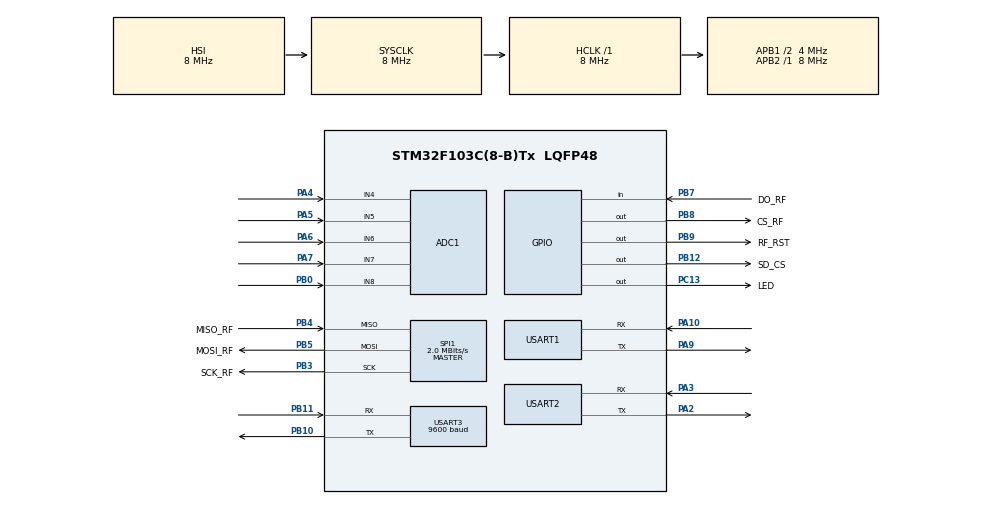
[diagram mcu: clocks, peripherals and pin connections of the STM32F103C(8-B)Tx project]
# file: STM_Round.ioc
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ADC1.Channel-0\#ChannelRegularConversion=ADC_CHANNEL_4
ADC1.Channel-1\#ChannelRegularConversion=ADC_CHANNEL_5
ADC1.Channel-2\#ChannelRegularConversion=ADC_CHANNEL_6
ADC1.Channel-3\#ChannelRegularConversion=ADC_CHANNEL_7
ADC1.Channel-4\#ChannelRegularConversion=ADC_CHANNEL_8
ADC1.ContinuousConvMode=ENABLE
ADC1.NbrOfConversion=5
ADC1.NbrOfConversionFlag=1
ADC1.Rank-0\#ChannelRegularConversion=1
ADC1.Rank-1\#ChannelRegularConversion=2
ADC1.Rank-2\#ChannelRegularConversion=3
ADC1.Rank-3\#ChannelRegularConversion=4
ADC1.Rank-4\#ChannelRegularConversion=5
ADC1.SamplingTime-0\#ChannelRegularConversion=ADC_SAMPLETIME_239CYCLES_5
ADC1.SamplingTime-1\#ChannelRegularConversion=ADC_SAMPLETIME_239CYCLES_5
ADC1.SamplingTime-2\#ChannelRegularConversion=ADC_SAMPLETIME_239CYCLES_5
ADC1.SamplingTime-3\#ChannelRegularConversion=ADC_SAMPLETIME_239CYCLES_5
ADC1.SamplingTime-4\#ChannelRegularConversion=ADC_SAMPLETIME_239CYCLES_5
ADC1.master=1
Dma.ADC1.1.Direction=DMA_PERIPH_TO_MEMORY
Dma.ADC1.1.Instance=DMA1_Channel1
Dma.ADC1.1.MemDataAlignment=DMA_MDATAALIGN_HALFWORD
Dma.ADC1.1.MemInc=DMA_MINC_ENABLE
Dma.ADC1.1.Mode=DMA_CIRCULAR
Dma.ADC1.1.PeriphDataAlignment=DMA_PDATAALIGN_HALFWORD
Dma.ADC1.1.PeriphInc=DMA_PINC_DISABLE
Dma.ADC1.1.Priority=DMA_PRIORITY_LOW
Dma.Request0=USART2_RX
Dma.Request1=ADC1
Dma.Request2=USART1_RX
Dma.USART1_RX.2.Direction=DMA_PERIPH_TO_MEMORY
Dma.USART1_RX.2.Instance=DMA1_Channel5
Dma.USART1_RX.2.MemDataAlignment=DMA_MDATAALIGN_BYTE
Dma.USART1_RX.2.MemInc=DMA_MINC_ENABLE
Dma.USART1_RX.2.Mode=DMA_NORMAL
Dma.USART1_RX.2.PeriphDataAlignment=DMA_PDATAALIGN_BYTE
Dma.USART1_RX.2.PeriphInc=DMA_PINC_DISABLE
Dma.USART1_RX.2.Priority=DMA_PRIORITY_LOW
Dma.USART2_RX.0.Direction=DMA_PERIPH_TO_MEMORY
Dma.USART2_RX.0.Instance=DMA1_Channel6
Dma.USART2_RX.0.MemDataAlignment=DMA_MDATAALIGN_BYTE
Dma.USART2_RX.0.MemInc=DMA_MINC_ENABLE
Dma.USART2_RX.0.Mode=DMA_NORMAL
Dma.USART2_RX.0.PeriphDataAlignment=DMA_PDATAALIGN_BYTE
Dma.USART2_RX.0.PeriphInc=DMA_PINC_DISABLE
Dma.USART2_RX.0.Priority=DMA_PRIORITY_LOW
Mcu.Family=STM32F1
Mcu.Name=STM32F103C(8-B)Tx
Mcu.Package=LQFP48
NVIC.DMA1_Channel1_IRQn=true\:0\:0\:false\:false\:true\:false\:true
NVIC.DMA1_Channel5_IRQn=true\:0\:0\:false\:false\:true\:false\:true
NVIC.DMA1_Channel6_IRQn=true\:1\:0\:true\:true\:true\:2\:false\:true
NVIC.PriorityGroup=NVIC_PRIORITYGROUP_4
NVIC.USART1_IRQn=true\:1\:0\:true\:true\:true\:3\:true\:true
NVIC.USART2_IRQn=true\:1\:0\:true\:true\:true\:4\:true\:true
NVIC.USART3_IRQn=true\:1\:0\:true\:true\:true\:5\:true\:true
PA10.Mode=Asynchronous
PA10.Signal=USART1_RX
PA13.Mode=Serial_Wire
PA13.Signal=SYS_JTMS-SWDIO
PA14.Mode=Serial_Wire
PA14.Signal=SYS_JTCK-SWCLK
PA2.Mode=Asynchronous
PA2.Signal=USART2_TX
PA3.Mode=Asynchronous
PA3.Signal=USART2_RX
PA4.Signal=ADCx_IN4
PA5.Signal=ADCx_IN5
PA6.Signal=ADCx_IN6
PA7.Signal=ADCx_IN7
PA9.Mode=Asynchronous
PA9.Signal=USART1_TX
PB0.Signal=ADCx_IN8
PB10.Mode=Asynchronous
PB10.Signal=USART3_TX
PB11.Mode=Asynchronous
PB11.Signal=USART3_RX
PB12.GPIO_Label=SD_CS
PB12.GPIO_Speed=GPIO_SPEED_FREQ_MEDIUM
PB12.Signal=GPIO_Output
PB3.GPIO_Label=SCK_RF
PB3.Mode=Full_Duplex_Master
PB3.Signal=SPI1_SCK
PB4.GPIO_Label=MISO_RF
PB4.Mode=Full_Duplex_Master
PB4.Signal=SPI1_MISO
PB5.GPIO_Label=MOSI_RF
PB5.Mode=Full_Duplex_Master
PB5.Signal=SPI1_MOSI
PB7.GPIO_Label=DO_RF
PB7.Signal=GPIO_Input
PB8.GPIO_Label=CS_RF
PB8.GPIO_Speed=GPIO_SPEED_FREQ_MEDIUM
PB8.PinState=GPIO_PIN_SET
PB8.Signal=GPIO_Output
PB9.GPIO_Label=RF_RST
PB9.PinState=GPIO_PIN_SET
PB9.Signal=GPIO_Output
PC13-TAMPER-RTC.GPIO_Label=LED
PC13-TAMPER-RTC.Signal=GPIO_Output
ProjectManager.HeapSize=0x200
ProjectManager.StackSize=0x400
ProjectManager.TargetToolchain=STM32CubeIDE
RCC.ADCPresc=RCC_ADCPCLK2_DIV6
RCC.AHBFreq_Value=8000000
RCC.APB1CLKDivider=RCC_HCLK_DIV2
RCC.APB1Freq_Value=4000000
RCC.APB1TimFreq_Value=8000000
RCC.APB2Freq_Value=8000000
RCC.APB2TimFreq_Value=8000000
RCC.HCLKFreq_Value=8000000
RCC.PLLMUL=RCC_PLL_MUL9
RCC.SYSCLKFreq_VALUE=8000000
RCC.USBFreq_Value=36000000
SH.ADCx_IN4.0=ADC1_IN4,IN4
SH.ADCx_IN5.0=ADC1_IN5,IN5
SH.ADCx_IN6.0=ADC1_IN6,IN6
SH.ADCx_IN7.0=ADC1_IN7,IN7
SH.ADCx_IN8.0=ADC1_IN8,IN8
SPI1.BaudRatePrescaler=SPI_BAUDRATEPRESCALER_4
SPI1.CalculateBaudRate=2.0 MBits/s
SPI1.Direction=SPI_DIRECTION_2LINES
SPI1.Mode=SPI_MODE_MASTER
SPI1.VirtualType=VM_MASTER
USART1.VirtualMode=VM_ASYNC
USART1.WordLength=WORDLENGTH_8B
USART2.VirtualMode=VM_ASYNC
USART3.BaudRate=9600
USART3.VirtualMode=VM_ASYNC
board=custom

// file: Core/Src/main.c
/* USER CODE BEGIN Header */
/**
 ******************************************************************************
 * @file           : main.c
 * @brief          : Main program body
 ******************************************************************************
 * @attention
 *
 * <h2><center>&copy; Copyright (c) 2021 STMicroelectronics.
 * All rights reserved.</center></h2>
 *
 * This software component is licensed by ST under BSD 3-Clause license,
 * the "License"; You may not use this file except in compliance with the
 * License. You may obtain a copy of the License at:
 *                        opensource.org/licenses/BSD-3-Clause
 *
 ******************************************************************************
 */
/* USER CODE END Header */
#include "main.h"
#include "adc.h"
#include "dma.h"
#include "spi.h"
#include "usart.h"
#include "gpio.h"

/* USER CODE BEGIN Includes */

#include "Funkcje.h"
#include <stdio.h>

/* USER CODE END Includes */

/* USER CODE BEGIN PV */

char odp[100] = "TNWN;DSTA";

/* USER CODE END PV */

void SystemClock_Config(void);
static void MX_NVIC_Init(void);

int main(void)
{

  /* MCU Configuration--------------------------------------------------------*/

  /* Reset of all peripherals, Initializes the Flash interface and the Systick. */
  HAL_Init();

  /* Configure the system clock */
  SystemClock_Config();

  /* Initialize all configured peripherals */
  MX_GPIO_Init();
  MX_DMA_Init();
  MX_SPI1_Init();
  MX_USART1_UART_Init();
  MX_USART2_UART_Init();
  MX_USART3_UART_Init();
  MX_ADC1_Init();

  /* Initialize interrupts */
  MX_NVIC_Init();
  /* USER CODE BEGIN 2 */

	HAL_Delay(1000);
	initAll();

  /* USER CODE END 2 */

  /* Infinite loop */
  /* USER CODE BEGIN WHILE */
	while (1) {

		// Sprawdzanie, czy przyszły dane z LoRy:
		loraLoop();
		if (loraBuffer[0] != 0)	loraReaction();

		GPS_Process();

		// Zapisywanie każdej ramki we flashu ESP:
		if (uwTick - tfsStruct.saveTimer > SAVE_PERIOD) {

			tfsStruct.saveTimer = uwTick;
			updateFrame();
		}

		// Wysyłanie jednej ramki co jakiś czas:
		if (uwTick - tfsStruct.frameTimer > FRAME_PERIOD) {

			tfsStruct.frameTimer = uwTick;
			generateAndSendFrame();
		}

    /* USER CODE END WHILE */

	}
}

void SystemClock_Config(void)
{
  RCC_OscInitTypeDef RCC_OscInitStruct = {0};
  RCC_ClkInitTypeDef RCC_ClkInitStruct = {0};
  RCC_PeriphCLKInitTypeDef PeriphClkInit = {0};

  /** Initializes the RCC Oscillators according to the specified parameters
  * in the RCC_OscInitTypeDef structure.
  */
  RCC_OscInitStruct.OscillatorType = RCC_OSCILLATORTYPE_HSI;
  RCC_OscInitStruct.HSIState = RCC_HSI_ON;
  RCC_OscInitStruct.HSICalibrationValue = RCC_HSICALIBRATION_DEFAULT;
  RCC_OscInitStruct.PLL.PLLState = RCC_PLL_NONE;
  if (HAL_RCC_OscConfig(&RCC_OscInitStruct) != HAL_OK)
  {
    Error_Handler();
  }
  /** Initializes the CPU, AHB and APB buses clocks
  */
  RCC_ClkInitStruct.ClockType = RCC_CLOCKTYPE_HCLK|RCC_CLOCKTYPE_SYSCLK
                              |RCC_CLOCKTYPE_PCLK1|RCC_CLOCKTYPE_PCLK2;
  RCC_ClkInitStruct.SYSCLKSource = RCC_SYSCLKSOURCE_HSI;
  RCC_ClkInitStruct.AHBCLKDivider = RCC_SYSCLK_DIV1;
  RCC_ClkInitStruct.APB1CLKDivider = RCC_HCLK_DIV2;
  RCC_ClkInitStruct.APB2CLKDivider = RCC_HCLK_DIV1;

  if (HAL_RCC_ClockConfig(&RCC_ClkInitStruct, FLASH_LATENCY_0) != HAL_OK)
  {
    Error_Handler();
  }
  PeriphClkInit.PeriphClockSelection = RCC_PERIPHCLK_ADC;
  PeriphClkInit.AdcClockSelection = RCC_ADCPCLK2_DIV6;
  if (HAL_RCCEx_PeriphCLKConfig(&PeriphClkInit) != HAL_OK)
  {
    Error_Handler();
  }
}

/**
  * @brief NVIC Configuration.
  * @retval None
  */
static void MX_NVIC_Init(void)
{
  /* DMA1_Channel6_IRQn interrupt configuration */
  HAL_NVIC_SetPriority(DMA1_Channel6_IRQn, 1, 0);
  HAL_NVIC_EnableIRQ(DMA1_Channel6_IRQn);
  /* USART1_IRQn interrupt configuration */
  HAL_NVIC_SetPriority(USART1_IRQn, 1, 0);
  HAL_NVIC_EnableIRQ(USART1_IRQn);
  /* USART2_IRQn interrupt configuration */
  HAL_NVIC_SetPriority(USART2_IRQn, 1, 0);
  HAL_NVIC_EnableIRQ(USART2_IRQn);
  /* USART3_IRQn interrupt configuration */
  HAL_NVIC_SetPriority(USART3_IRQn, 1, 0);
  HAL_NVIC_EnableIRQ(USART3_IRQn);
}

void Error_Handler(void)
{
	__disable_irq();
	while (1) {
	}
}
